AUTOSAR XML (schema 4-3-0)
package /ComponentTypes
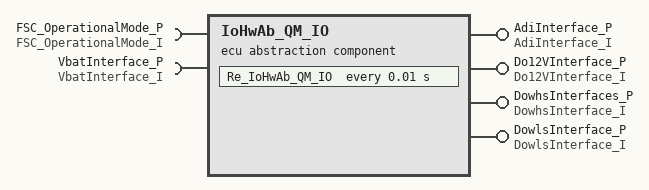
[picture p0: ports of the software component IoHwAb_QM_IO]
  ecu abstraction sw component type IoHwAb_QM_IO
    require port FSC_OperationalMode_P: required-com-specs=[FSC_OperationalMode, VbatInterface_P], required-interface=FSC_OperationalMode_I
    require port VbatInterface_P: required-interface=VbatInterface_I
      required-com-specs:
        DobhsCtrlInterface_P_4
        DobhsCtrlInterface_P_5
        DobhsCtrlInterface_P_3
        DobhsCtrlInterface_P_2
        DobhsCtrlInterface_P_1
        FSC_OperationalMode
        VbatInterface_P
    4 x provide port:
      AdiInterface_P: provided-interface=AdiInterface_I
        provided-com-specs:
          operation=SetPullUp, queue-length=1
          operation=GetPullUpState, queue-length=1
          operation=GetAdiPinStateAll, queue-length=1
          operation=GetAdiPinState, queue-length=1
      Do12VInterface_P: provided-interface=Do12VInterface_I
        provided-com-specs:
          operation=SetDo12VParkedActive, queue-length=1
          operation=SetDo12VLivingActive, queue-length=1
          operation=SetDcdc12VActive, queue-length=1
          operation=GetDo12VPinsState, queue-length=1
      DowhsInterfaces_P: provided-com-specs=[{operation=SetDowActive, queue-length=1}, {operation=GetDoPinStateOne, queue-length=1}], provided-interface=DowhsInterface_I
      DowlsInterface_P: provided-com-specs=[{operation=SetDowlsActive, queue-length=1}, {operation=GetDoPinStateOne, queue-length=1}], provided-interface=DowlsInterface_I
    behavior IoHwAb_QM_IO_InternalBehavior
      timing event TMT_Re_IoHwAb_QM_IO: start-on-event=Re_IoHwAb_QM_IO, period=0.01
      runnable Re_IoHwAb_QM_IO
  swc implementation IoHwAb_QM_IO_Implementation: behavior=IoHwAb_QM_IO_InternalBehavior
